# RL6678_IP_SVD register map
Vendor: Realtek
Registers are 32-bit, read-write, reset 0x0 unless marked. A register's access mark holds for its fields unless they carry their own. Offsets are from the block's base; [hi:lo] are bit positions; lines under a group give offsets from that group; {n}, {i} and the like mark numbered series; 'fields as' and 'values as' point back to an identical list.

## PINMUX_REG
Base 0x42008A00
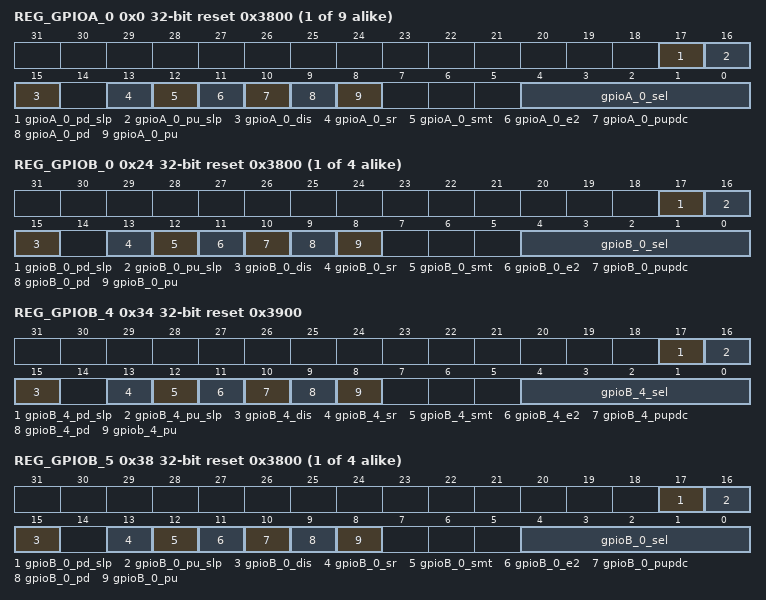
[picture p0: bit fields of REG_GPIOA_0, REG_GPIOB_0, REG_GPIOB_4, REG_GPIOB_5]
{0x0+4i} REG_GPIOA_{i} reset 0x3800 (i=0..8)
  [17] gpioA_{i}_pd_slp — PAD pull down enable when system is in sleep.
  [16] gpioA_{i}_pu_slp — PAD pull up enable when system is in sleep.
  [15] gpioA_{i}_dis — PAD shutdown, only when the whole group's dis signals are all 1, the PAD SHDN will pull down to shutdown the group pad. 1. disable pad 0. enable pad
  [13] gpioA_{i}_sr — PAD srew rate control
  [12] gpioA_{i}_smt — PAD Schmit control
  [11] gpioA_{i}_e2 — PAD driving ability control. 0: low 1: high The actual driving current is depend on pad type.
  [10] gpioA_{i}_pupdc — Some pad may have two type of PU/PD resistor, this bit can select it. 1: small resistor 0: big resistor
  [9] gpioA_{i}_pd — PAD pull down enable when system is in active.
  [8] gpioA_{i}_pu — PAD pull up enable when system is in active.
  [4:0] gpioA_{i}_sel — PAD pinmux function ID selection
{0x24+4i} REG_GPIOB_{i} reset 0x3800 (i=0..3)
  [17] gpioB_{i}_pd_slp — PAD pull down enable when system is in sleep.
  [16] gpioB_{i}_pu_slp — PAD pull up enable when system is in sleep.
  [15] gpioB_{i}_dis — PAD shutdown, only when the whole group's dis signals are all 1, the PAD SHDN will pull down to shutdown the group pad. 1. disable pad 0. enable pad
  [13] gpioB_{i}_sr — PAD srew rate control
  [12] gpioB_{i}_smt — PAD Schmit control
  [11] gpioB_{i}_e2 — PAD driving ability control. 0: low 1: high The actual driving current is depend on pad type.
  [10] gpioB_{i}_pupdc — Some pad may have two type of PU/PD resistor, this bit can select it. 1: small resistor 0: big resistor
  [9] gpioB_{i}_pd — PAD pull down enable when system is in active.
  [8] gpioB_{i}_pu — PAD pull up enable when system is in active.
  [4:0] gpioB_{i}_sel — PAD pinmux function ID selection
0x34 REG_GPIOB_4 reset 0x3900
  [17] gpioB_4_pd_slp — PAD pull down enable when system is in sleep.
  [16] gpioB_4_pu_slp — PAD pull up enable when system is in sleep.
  [15] gpioB_4_dis — PAD shutdown, only when the whole group's dis signals are all 1, the PAD SHDN will pull down to shutdown the group pad. 1. disable pad 0. enable pad
  [13] gpioB_4_sr — PAD srew rate control
  [12] gpioB_4_smt — PAD Schmit control
  [11] gpioB_4_e2 — PAD driving ability control. 0: low 1: high The actual driving current is depend on pad type.
  [10] gpioB_4_pupdc — Some pad may have two type of PU/PD resistor, this bit can select it. 1: small resistor 0: big resistor
  [9] gpioB_4_pd — PAD pull down enable when system is in active.
  [8] gpiob_4_pu — PAD pull up enable when system is in active.
  [4:0] gpioB_4_sel — PAD pinmux function ID selection
{0x24+4i} REG_GPIOB_{i} reset 0x3800 (i=5..8)
  fields as REG_GPIOB_0
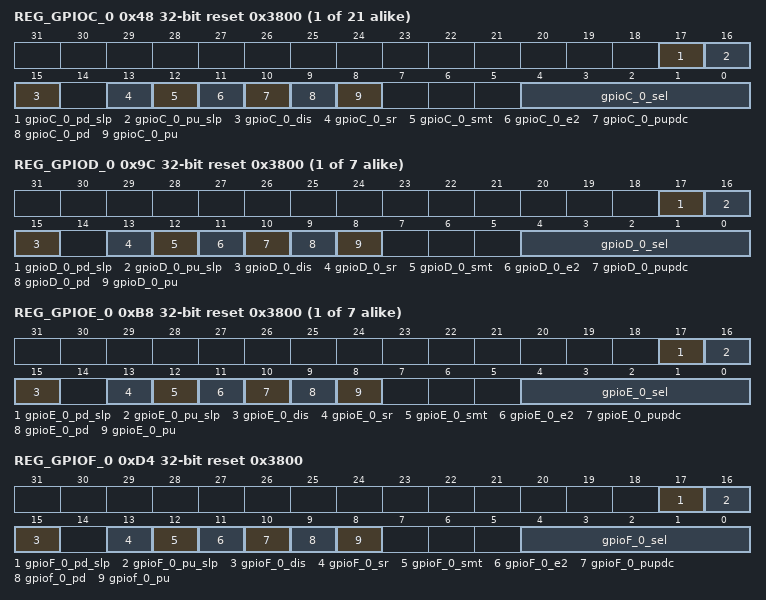
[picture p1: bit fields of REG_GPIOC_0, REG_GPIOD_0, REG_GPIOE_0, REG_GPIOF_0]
{0x48+4i} REG_GPIOC_{i} reset 0x3800 (i=0..20)
  [17] gpioC_{i}_pd_slp — PAD pull down enable when system is in sleep.
  [16] gpioC_{i}_pu_slp — PAD pull up enable when system is in sleep.
  [15] gpioC_{i}_dis — PAD shutdown, only when the whole group's dis signals are all 1, the PAD SHDN will pull down to shutdown the group pad. 1. disable pad 0. enable pad
  [13] gpioC_{i}_sr — PAD srew rate control
  [12] gpioC_{i}_smt — PAD Schmit control
  [11] gpioC_{i}_e2 — PAD driving ability control. 0: low 1: high The actual driving current is depend on pad type.
  [10] gpioC_{i}_pupdc — Some pad may have two type of PU/PD resistor, this bit can select it. 1: small resistor 0: big resistor
  [9] gpioC_{i}_pd — PAD pull down enable when system is in active.
  [8] gpioC_{i}_pu — PAD pull up enable when system is in active.
  [4:0] gpioC_{i}_sel — PAD pinmux function ID selection
{0x9C+4i} REG_GPIOD_{i} reset 0x3800 (i=0..6)
  [17] gpioD_{i}_pd_slp — PAD pull down enable when system is in sleep.
  [16] gpioD_{i}_pu_slp — PAD pull up enable when system is in sleep.
  [15] gpioD_{i}_dis — PAD shutdown, only when the whole group's dis signals are all 1, the PAD SHDN will pull down to shutdown the group pad. 1. disable pad 0. enable pad
  [13] gpioD_{i}_sr — PAD srew rate control
  [12] gpioD_{i}_smt — PAD Schmit control
  [11] gpioD_{i}_e2 — PAD driving ability control. 0: low 1: high The actual driving current is depend on pad type.
  [10] gpioD_{i}_pupdc — Some pad may have two type of PU/PD resistor, this bit can select it. 1: small resistor 0: big resistor
  [9] gpioD_{i}_pd — PAD pull down enable when system is in active.
  [8] gpioD_{i}_pu — PAD pull up enable when system is in active.
  [4:0] gpioD_{i}_sel — PAD pinmux function ID selection
{0xB8+4i} REG_GPIOE_{i} reset 0x3800 (i=0..6)
  [17] gpioE_{i}_pd_slp — PAD pull down enable when system is in sleep.
  [16] gpioE_{i}_pu_slp — PAD pull up enable when system is in sleep.
  [15] gpioE_{i}_dis — PAD shutdown, only when the whole group's dis signals are all 1, the PAD SHDN will pull down to shutdown the group pad. 1. disable pad 0. enable pad
  [13] gpioE_{i}_sr — PAD srew rate control
  [12] gpioE_{i}_smt — PAD Schmit control
  [11] gpioE_{i}_e2 — PAD driving ability control. 0: low 1: high The actual driving current is depend on pad type.
  [10] gpioE_{i}_pupdc — Some pad may have two type of PU/PD resistor, this bit can select it. 1: small resistor 0: big resistor
  [9] gpioE_{i}_pd — PAD pull down enable when system is in active.
  [8] gpioE_{i}_pu — PAD pull up enable when system is in active.
  [4:0] gpioE_{i}_sel — PAD pinmux function ID selection
0xD4 REG_GPIOF_0 reset 0x3800
  [17] gpioF_0_pd_slp — PAD pull down enable when system is in sleep.
  [16] gpioF_0_pu_slp — PAD pull up enable when system is in sleep.
  [15] gpioF_0_dis — PAD shutdown, only when the whole group's dis signals are all 1, the PAD SHDN will pull down to shutdown the group pad. 1. disable pad 0. enable pad
  [13] gpioF_0_sr — PAD srew rate control
  [12] gpioF_0_smt — PAD Schmit control
  [11] gpioF_0_e2 — PAD driving ability control. 0: low 1: high The actual driving current is depend on pad type.
  [10] gpioF_0_pupdc — Some pad may have two type of PU/PD resistor, this bit can select it. 1: small resistor 0: big resistor
  [9] gpiof_0_pd — PAD pull down enable when system is in active.
  [8] gpiof_0_pu — PAD pull up enable when system is in active.
  [4:0] gpioF_0_sel — PAD pinmux function ID selection
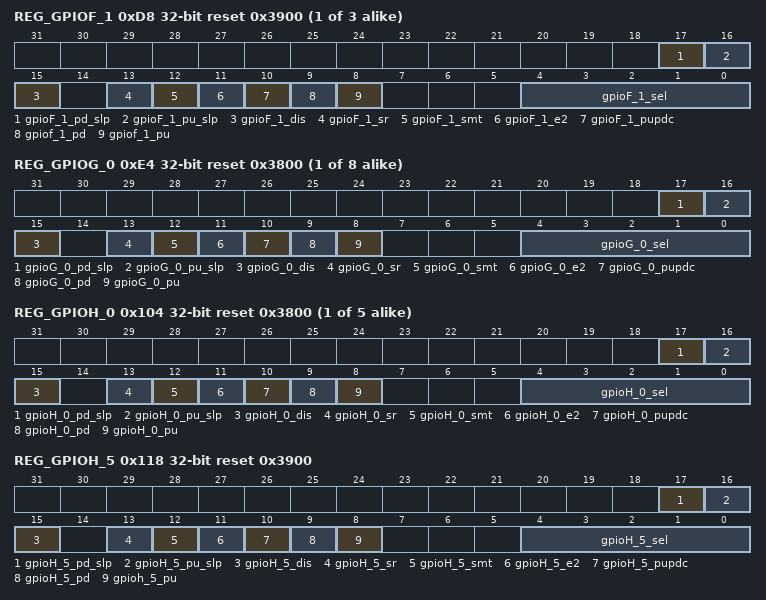
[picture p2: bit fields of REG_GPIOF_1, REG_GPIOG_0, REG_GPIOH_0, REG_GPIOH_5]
{0xD4+4i} REG_GPIOF_{i} reset 0x3900 (i=1..3)
  [17] gpioF_{i}_pd_slp — PAD pull down enable when system is in sleep.
  [16] gpioF_{i}_pu_slp — PAD pull up enable when system is in sleep.
  [15] gpioF_{i}_dis — PAD shutdown, only when the whole group's dis signals are all 1, the PAD SHDN will pull down to shutdown the group pad. 1. disable pad 0. enable pad
  [13] gpioF_{i}_sr — PAD srew rate control
  [12] gpioF_{i}_smt — PAD Schmit control
  [11] gpioF_{i}_e2 — PAD driving ability control. 0: low 1: high The actual driving current is depend on pad type.
  [10] gpioF_{i}_pupdc — Some pad may have two type of PU/PD resistor, this bit can select it. 1: small resistor 0: big resistor
  [9] gpiof_{i}_pd — PAD pull down enable when system is in active.
  [8] gpiof_{i}_pu — PAD pull up enable when system is in active.
  [4:0] gpioF_{i}_sel — PAD pinmux function ID selection
{0xE4+4i} REG_GPIOG_{i} reset 0x3800 (i=0..7)
  [17] gpioG_{i}_pd_slp — PAD pull down enable when system is in sleep.
  [16] gpioG_{i}_pu_slp — PAD pull up enable when system is in sleep.
  [15] gpioG_{i}_dis — PAD shutdown, only when the whole group's dis signals are all 1, the PAD SHDN will pull down to shutdown the group pad. 1. disable pad 0. enable pad
  [13] gpioG_{i}_sr — PAD srew rate control
  [12] gpioG_{i}_smt — PAD Schmit control
  [11] gpioG_{i}_e2 — PAD driving ability control. 0: low 1: high The actual driving current is depend on pad type.
  [10] gpioG_{i}_pupdc — Some pad may have two type of PU/PD resistor, this bit can select it. 1: small resistor 0: big resistor
  [9] gpioG_{i}_pd — PAD pull down enable when system is in active.
  [8] gpioG_{i}_pu — PAD pull up enable when system is in active.
  [4:0] gpioG_{i}_sel — PAD pinmux function ID selection
{0x104+4i} REG_GPIOH_{i} reset 0x3800 (i=0..4)
  [17] gpioH_{i}_pd_slp — PAD pull down enable when system is in sleep.
  [16] gpioH_{i}_pu_slp — PAD pull up enable when system is in sleep.
  [15] gpioH_{i}_dis — PAD shutdown, only when the whole group's dis signals are all 1, the PAD SHDN will pull down to shutdown the group pad. 1. disable pad 0. enable pad
  [13] gpioH_{i}_sr — PAD srew rate control
  [12] gpioH_{i}_smt — PAD Schmit control
  [11] gpioH_{i}_e2 — PAD driving ability control. 0: low 1: high The actual driving current is depend on pad type.
  [10] gpioH_{i}_pupdc — Some pad may have two type of PU/PD resistor, this bit can select it. 1: small resistor 0: big resistor
  [9] gpioH_{i}_pd — PAD pull down enable when system is in active.
  [8] gpioH_{i}_pu — PAD pull up enable when system is in active.
  [4:0] gpioH_{i}_sel — PAD pinmux function ID selection
0x118 REG_GPIOH_5 reset 0x3900
  [17] gpioH_5_pd_slp — PAD pull down enable when system is in sleep.
  [16] gpioH_5_pu_slp — PAD pull up enable when system is in sleep.
  [15] gpioH_5_dis — PAD shutdown, only when the whole group's dis signals are all 1, the PAD SHDN will pull down to shutdown the group pad. 1. disable pad 0. enable pad
  [13] gpioH_5_sr — PAD srew rate control
  [12] gpioH_5_smt — PAD Schmit control
  [11] gpioH_5_e2 — PAD driving ability control. 0: low 1: high The actual driving current is depend on pad type.
  [10] gpioH_5_pupdc — Some pad may have two type of PU/PD resistor, this bit can select it. 1: small resistor 0: big resistor
  [9] gpioH_5_pd — PAD pull down enable when system is in active.
  [8] gpioh_5_pu — PAD pull up enable when system is in active.
  [4:0] gpioH_5_sel — PAD pinmux function ID selection
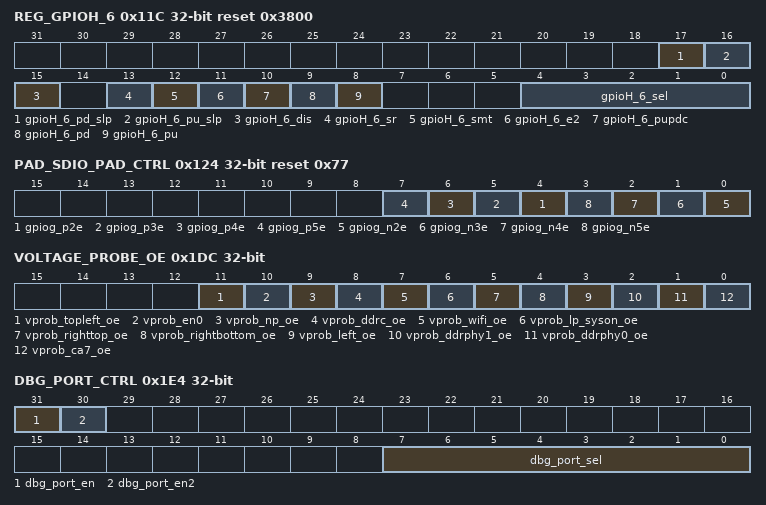
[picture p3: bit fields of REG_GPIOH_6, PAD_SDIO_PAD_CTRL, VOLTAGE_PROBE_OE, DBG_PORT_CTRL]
0x11C REG_GPIOH_6 reset 0x3800
  [17] gpioH_6_pd_slp — PAD pull down enable when system is in sleep.
  [16] gpioH_6_pu_slp — PAD pull up enable when system is in sleep.
  [15] gpioH_6_dis — PAD shutdown, only when the whole group's dis signals are all 1, the PAD SHDN will pull down to shutdown the group pad. 1. disable pad 0. enable pad
  [13] gpioH_6_sr — PAD srew rate control
  [12] gpioH_6_smt — PAD Schmit control
  [11] gpioH_6_e2 — PAD driving ability control. 0: low 1: high The actual driving current is depend on pad type.
  [10] gpioH_6_pupdc — Some pad may have two type of PU/PD resistor, this bit can select it. 1: small resistor 0: big resistor
  [9] gpioH_6_pd — PAD pull down enable when system is in active.
  [8] gpioH_6_pu — PAD pull up enable when system is in active.
  [4:0] gpioH_6_sel — PAD pinmux function ID selection
0x120 PAD_AUD_PAD_CTRL
  [20:0] gpioc_ie — Audio share pad input enable.
0x124 PAD_SDIO_PAD_CTRL reset 0x77
  [n+2] gpiog_p{n}e (n=2..5) — SDIO pad drive control. All SDIO pad share the same parameter.
  [n-2] gpiog_n{n}e (n=2..5) — SDIO pad drive control. All SDIO pad share the same parameter.
0x1DC VOLTAGE_PROBE_OE
  [11] vprob_topleft_oe — add in MP
  [10] vprob_en0
  [9] vprob_np_oe
  [8] vprob_ddrc_oe
  [7] vprob_wifi_oe
  [6] vprob_lp_syson_oe
  [5] vprob_righttop_oe
  [4] vprob_rightbottom_oe
  [3] vprob_left_oe
  [2] vprob_ddrphy1_oe
  [1] vprob_ddrphy0_oe
  [0] vprob_ca7_oe
0x1E4 DBG_PORT_CTRL
  [31] dbg_port_en — enable dbgmux function
  [30] dbg_port_en2 — Write this bit to trigger all GPIO pad's FUNC ID changes to debug port function. After writing this bit, the sel bits in every pad register will change to FUNC debug port value. And this bit will be cleared by HW.
  [7:0] dbg_port_sel — select the debug port's specific connection with different IP. The specific relationship is refered to the dbg port spec.
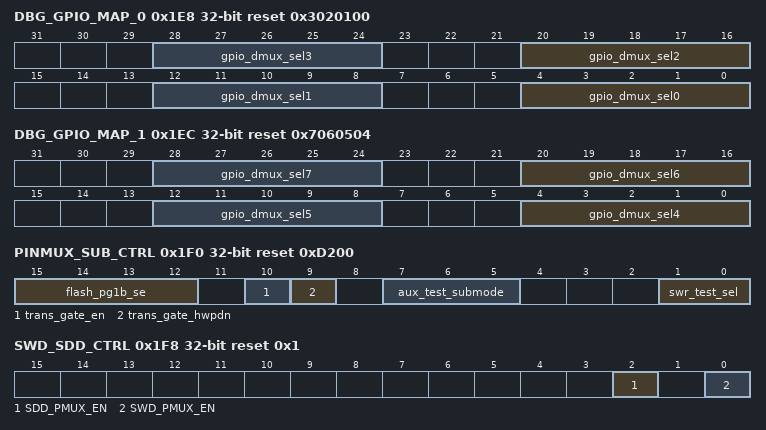
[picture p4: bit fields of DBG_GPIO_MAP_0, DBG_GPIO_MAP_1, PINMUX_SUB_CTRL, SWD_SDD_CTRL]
0x1E8 DBG_GPIO_MAP_0 reset 0x3020100
  [8n+4:8n] gpio_dmux_sel{n} (n=0..3)
0x1EC DBG_GPIO_MAP_1 reset 0x7060504
  [8n-28:8n-32] gpio_dmux_sel{n} (n=4..7)
0x1F0 PINMUX_SUB_CTRL reset 0xD200
  [15:12] flash_pg1b_se — When TestMode 13 , using 1bit mode to pg MCM flash using ext pin . [0] : if 1 , ext spi_data0 pin fix to input , if 0 ext spi_data0 pin fix to output [1] : if 1 , ext spi_data1 pin fix to input , if 0 ext spi_data1 pin fix to output [2] : if 1 , ext spi_data2 pin fix to input , if 0 ext spi_data2 pin fix to output [3] : if 1 , ext spi_data3 pin fix to input , if 0 ext spi_data3 pin fix to output default is : 1101 which only data1 using as output.
  [10] trans_gate_en
  [9] trans_gate_hwpdn
  [7:5] aux_test_submode — 000: aux adc test 001: flash pll 010: i2s pll 011: i2s signal 100: debug clock 101: power
  [1:0] swr_test_sel — 00/11: swr core test out 01: aud/psram swr test out 10: ddr mem swr test out
0x1F8 SWD_SDD_CTRL reset 0x1
  [2] SDD_PMUX_EN — 1: Enable SDIO pinmux enable function 0: Disable
  [0] SWD_PMUX_EN — 1: Enable SWD pinmux enable function 0: Disable SWD_LOC is valid only when this bit is 1.
